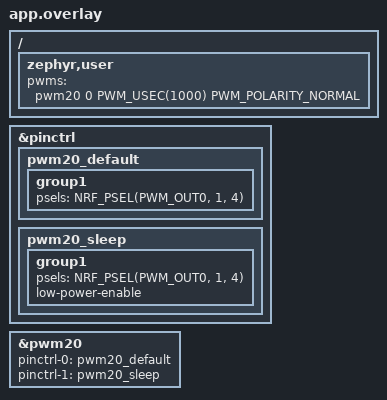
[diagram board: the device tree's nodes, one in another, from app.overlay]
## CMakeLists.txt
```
cmake_minimum_required(VERSION 3.20.0)
find_package(Zephyr REQUIRED HINTS $ENV{ZEPHYR_BASE})
project(pwm_output)
if(NOT TARGET nrf54l15_core)
  add_subdirectory(../../lib/nrf54l15 ${CMAKE_CURRENT_BINARY_DIR}/nrf54l15)
endif()
target_sources(app PRIVATE src/main.c)
target_link_libraries(app PRIVATE nrf54l15_drivers)
```

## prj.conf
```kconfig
CONFIG_PWM=y
CONFIG_PRINTK=y
CONFIG_CONSOLE=y
CONFIG_UART_CONSOLE=y
CONFIG_SENSOR=n
CONFIG_ADC=n
CONFIG_MAIN_STACK_SIZE=2048
```

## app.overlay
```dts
#include <zephyr/dt-bindings/pwm/pwm.h>

/* Hardware PWM must use P1. The built-in XIAO LED is on P2.00.
 * This standalone example drives D0/A0 (P1.04) instead, at nominal 1 kHz.
 */
/ {
	zephyr,user {
		pwms = <&pwm20 0 PWM_USEC(1000) PWM_POLARITY_NORMAL>;
	};
};

&pinctrl {
	pwm20_default: pwm20_default {
		group1 {
			psels = <NRF_PSEL(PWM_OUT0, 1, 4)>;
		};
	};
	pwm20_sleep: pwm20_sleep {
		group1 {
			psels = <NRF_PSEL(PWM_OUT0, 1, 4)>;
			low-power-enable;
		};
	};
};

&pwm20 {
	status = "okay";
	pinctrl-0 = <&pwm20_default>;
	pinctrl-1 = <&pwm20_sleep>;
	pinctrl-names = "default", "sleep";
};
```

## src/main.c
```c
/* SPDX-License-Identifier: Apache-2.0 */
#include <zephyr/kernel.h>
#include <nrf54l15/pwm.h>

static const struct pwm_dt_spec pin = PWM_DT_SPEC_GET(DT_PATH(zephyr_user));

int main(void)
{
	struct nrf54l15_pwm output;
	int err = nrf54l15_pwm_init(&output, &pin);
	if (err) {
		printk("# PWM init failed: %d\n", err);
		return err;
	}
	printk("# PWM on XIAO D0/A0 (P1.04), period_ns=%u\n", pin.period);
	printk("# PWM,duty_permille (external LED or scope)\n");
	int duty = 0;
	int step = 10;
	while (true) {
		err = nrf54l15_pwm_set_duty_permille(&output, (uint16_t)duty);
		if (err) {
			printk("# PWM update failed: %d\n", err);
			int inactive_err = nrf54l15_pwm_set_duty_permille(&output, 0);
			if (inactive_err) {
				printk("# PWM inactive request also failed: %d\n", inactive_err);
			}
			return err;
		}
		if (duty % 250 == 0) {
			printk("PWM,%d\n", duty);
		}
		if (duty == 1000) {
			step = -10;
		} else if (duty == 0) {
			step = 10;
		}
		duty += step;
		k_sleep(K_MSEC(10));
	}
}
```
